AUTOSAR XML (schema 4-3-1)
package /Components
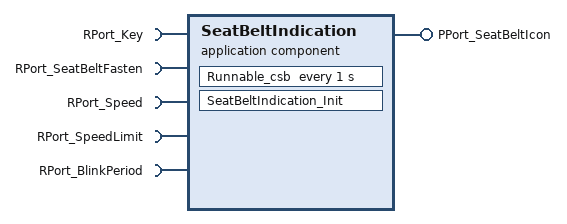
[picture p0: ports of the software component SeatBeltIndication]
  application sw component type SeatBeltIndication
    5 x require port:
      RPort_Key: nonqueued-receiver-com-spec{data-element=RPort_Key, init-value=0}, required-interface=RPort_Key
      RPort_SeatBeltFasten: nonqueued-receiver-com-spec{data-element=RPort_SeatBeltFasten, init-value=0}, required-interface=RPort_SeatBeltFasten
      RPort_Speed: nonqueued-receiver-com-spec{data-element=RPort_Speed, init-value=0}, required-interface=RPort_Speed
      RPort_SpeedLimit: nonqueued-receiver-com-spec{data-element=RPort_SpeedLimit, init-value=0}, required-interface=RPort_SpeedLimit
      RPort_BlinkPeriod: nonqueued-receiver-com-spec{data-element=RPort_BlinkPeriod, init-value=0}, required-interface=RPort_BlinkPeriod
    provide port PPort_SeatBeltIcon: nonqueued-sender-com-spec{data-element=PPort_SeatBeltIcon, init-value=0}, provided-interface=PPort_SeatBeltIcon
    behavior SeatBeltIndication_IB: handle-termination-and-restart=NO-SUPPORT
      timing event Event_Runnable_csb: start-on-event=Runnable_csb, period=1
      runnable SeatBeltIndication_Init
      runnable Runnable_csb
        data-read-access:
          5 x access:
            IN_RPort_BlinkPeriod_RPort_BlinkPeriod: accessed-variable=RPort_BlinkPeriod.RPort_BlinkPeriod
            IN_RPort_Key_RPort_Key: accessed-variable=RPort_Key.RPort_Key
            IN_RPort_SeatBeltFasten_RPort_SeatBeltFasten: accessed-variable=RPort_SeatBeltFasten.RPort_SeatBeltFasten
            IN_RPort_Speed_RPort_Speed: accessed-variable=RPort_Speed.RPort_Speed
            IN_RPort_SpeedLimit_RPort_SpeedLimit: accessed-variable=RPort_SpeedLimit.RPort_SpeedLimit
        data-write-access:
          access OUT_PPort_SeatBeltIcon_PPort_SeatBeltIcon: accessed-variable=PPort_SeatBeltIcon.PPort_SeatBeltIcon
